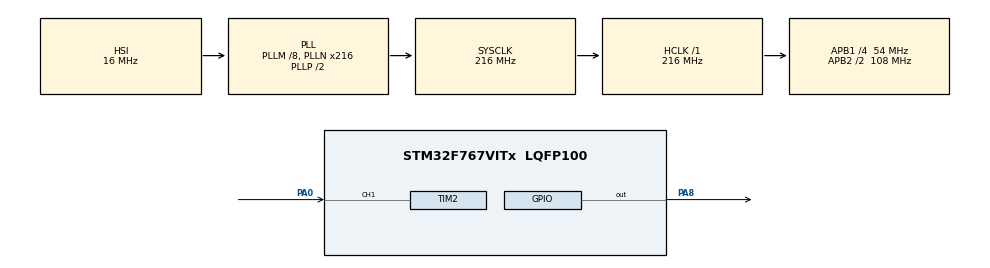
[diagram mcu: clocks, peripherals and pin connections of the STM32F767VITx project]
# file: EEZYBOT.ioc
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FREERTOS.Tasks01=defaultTask,24,128,StartDefaultTask,Default,NULL,Dynamic,NULL,NULL;Blink,8,128,StartBlink,Default,NULL,Dynamic,NULL,NULL
Mcu.Family=STM32F7
Mcu.Name=STM32F767VITx
Mcu.Package=LQFP100
NVIC.PriorityGroup=NVIC_PRIORITYGROUP_4
NVIC.TIM1_UP_TIM10_IRQn=true\:0\:0\:false\:false\:true\:false\:false\:true
NVIC.TIM2_IRQn=true\:5\:0\:false\:false\:true\:true\:true\:true
NVIC.TimeBase=TIM1_UP_TIM10_IRQn
NVIC.TimeBaseIP=TIM1
PA0/WKUP.GPIO_PuPd=GPIO_PULLDOWN
PA0/WKUP.Signal=S_TIM2_CH1_ETR
PA13.Mode=Serial_Wire
PA13.Signal=SYS_JTMS-SWDIO
PA14.Mode=Serial_Wire
PA14.Signal=SYS_JTCK-SWCLK
PA8.Signal=GPIO_Output
ProjectManager.HeapSize=0x200
ProjectManager.StackSize=0x400
ProjectManager.TargetToolchain=STM32CubeIDE
RCC.AHBFreq_Value=216000000
RCC.APB1CLKDivider=RCC_HCLK_DIV4
RCC.APB1Freq_Value=54000000
RCC.APB1TimFreq_Value=108000000
RCC.APB2CLKDivider=RCC_HCLK_DIV2
RCC.APB2Freq_Value=108000000
RCC.APB2TimFreq_Value=216000000
RCC.CortexFreq_Value=216000000
RCC.HCLKFreq_Value=216000000
RCC.HSE_VALUE=25000000
RCC.HSI_VALUE=16000000
RCC.LSE_VALUE=32768
RCC.PLLM=8
RCC.PLLN=216
RCC.SYSCLKFreq_VALUE=216000000
RCC.SYSCLKSource=RCC_SYSCLKSOURCE_PLLCLK
RCC.USBFreq_Value=216000000
RCC.VCOOutputFreq_Value=432000000
SH.S_TIM2_CH1_ETR.0=TIM2_CH1,Input_Capture1_from_TI1
TIM2.Channel-Input_Capture1_from_TI1=TIM_CHANNEL_1
TIM2.ICPolarity_CH1=TIM_INPUTCHANNELPOLARITY_RISING
TIM2.Period=216000
TIM2.Prescaler=0
VP_FREERTOS_VS_CMSIS_V2.Mode=CMSIS_V2
VP_SYS_VS_tim1.Mode=TIM1
board=custom

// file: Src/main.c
/* USER CODE BEGIN Header */
/**
  ******************************************************************************
  * @file           : main.c
  * @brief          : Main program body
  ******************************************************************************
  * @attention
  *
  * <h2><center>&copy; Copyright (c) 2020 STMicroelectronics.
  * All rights reserved.</center></h2>
  *
  * This software component is licensed by ST under BSD 3-Clause license,
  * the "License"; You may not use this file except in compliance with the
  * License. You may obtain a copy of the License at:
  *                        opensource.org/licenses/BSD-3-Clause
  *
  ******************************************************************************
  */
/* USER CODE END Header */

#include "main.h"
#include "cmsis_os.h"

/* USER CODE BEGIN Includes */
#include "AS5048.h"
/* USER CODE END Includes */

TIM_HandleTypeDef htim2;

/* Definitions for defaultTask */
osThreadId_t defaultTaskHandle;
const osThreadAttr_t defaultTask_attributes = {
  .name = "defaultTask",
  .priority = (osPriority_t) osPriorityNormal,
  .stack_size = 128 * 4
};
/* Definitions for Blink */
osThreadId_t BlinkHandle;
const osThreadAttr_t Blink_attributes = {
  .name = "Blink",
  .priority = (osPriority_t) osPriorityLow,
  .stack_size = 128 * 4
};

void SystemClock_Config(void);
static void MX_GPIO_Init(void);
static void MX_TIM2_Init(void);
void StartDefaultTask(void *argument);
void StartBlink(void *argument);

/* USER CODE BEGIN 0 */

AS5048_PWM_SENSOR position_sensors[3];

void HAL_TIM_IC_CaptureCallback(TIM_HandleTypeDef *htim){

	// Check if interrupt came from one of the sensors, then handle it
	for(int i = 0; i < 3; i++)
		if(htim->Instance == position_sensors[i].instance && htim->Channel == position_sensors[i].channel)
			AS5048_pwm_timer_interrupt(&position_sensors[i]);
}

/* USER CODE END 0 */

int main(void)
{

  /* MCU Configuration--------------------------------------------------------*/

  /* Reset of all peripherals, Initializes the Flash interface and the Systick. */
  HAL_Init();

  /* Configure the system clock */
  SystemClock_Config();

  /* Initialize all configured peripherals */
  MX_GPIO_Init();
  MX_TIM2_Init();
  /* USER CODE BEGIN 2 */

  HAL_TIM_IC_Start_IT(&htim2, TIM_CHANNEL_1);
  // Initialise sensor with timer
  AS5048_initialise_struct(&position_sensors[0], &htim2, TIM2, HAL_TIM_ACTIVE_CHANNEL_1, TIM_CHANNEL_1, 108000000);

  /* USER CODE END 2 */

  /* Init scheduler */
  osKernelInitialize();

  /* Create the thread(s) */
  /* creation of defaultTask */
  defaultTaskHandle = osThreadNew(StartDefaultTask, NULL, &defaultTask_attributes);

  /* creation of Blink */
  BlinkHandle = osThreadNew(StartBlink, NULL, &Blink_attributes);

  /* Start scheduler */
  osKernelStart();

  /* We should never get here as control is now taken by the scheduler */
  /* Infinite loop */
  while (1)
  {

  }
}

void SystemClock_Config(void)
{
  RCC_OscInitTypeDef RCC_OscInitStruct = {0};
  RCC_ClkInitTypeDef RCC_ClkInitStruct = {0};

  /** Configure the main internal regulator output voltage
  */
  __HAL_RCC_PWR_CLK_ENABLE();
  __HAL_PWR_VOLTAGESCALING_CONFIG(PWR_REGULATOR_VOLTAGE_SCALE1);
  /** Initializes the CPU, AHB and APB busses clocks
  */
  RCC_OscInitStruct.OscillatorType = RCC_OSCILLATORTYPE_HSI;
  RCC_OscInitStruct.HSIState = RCC_HSI_ON;
  RCC_OscInitStruct.HSICalibrationValue = RCC_HSICALIBRATION_DEFAULT;
  RCC_OscInitStruct.PLL.PLLState = RCC_PLL_ON;
  RCC_OscInitStruct.PLL.PLLSource = RCC_PLLSOURCE_HSI;
  RCC_OscInitStruct.PLL.PLLM = 8;
  RCC_OscInitStruct.PLL.PLLN = 216;
  RCC_OscInitStruct.PLL.PLLP = RCC_PLLP_DIV2;
  RCC_OscInitStruct.PLL.PLLQ = 2;
  if (HAL_RCC_OscConfig(&RCC_OscInitStruct) != HAL_OK)
  {
    Error_Handler();
  }
  /** Activate the Over-Drive mode
  */
  if (HAL_PWREx_EnableOverDrive() != HAL_OK)
  {
    Error_Handler();
  }
  /** Initializes the CPU, AHB and APB busses clocks
  */
  RCC_ClkInitStruct.ClockType = RCC_CLOCKTYPE_HCLK|RCC_CLOCKTYPE_SYSCLK
                              |RCC_CLOCKTYPE_PCLK1|RCC_CLOCKTYPE_PCLK2;
  RCC_ClkInitStruct.SYSCLKSource = RCC_SYSCLKSOURCE_PLLCLK;
  RCC_ClkInitStruct.AHBCLKDivider = RCC_SYSCLK_DIV1;
  RCC_ClkInitStruct.APB1CLKDivider = RCC_HCLK_DIV4;
  RCC_ClkInitStruct.APB2CLKDivider = RCC_HCLK_DIV2;

  if (HAL_RCC_ClockConfig(&RCC_ClkInitStruct, FLASH_LATENCY_7) != HAL_OK)
  {
    Error_Handler();
  }
}

static void MX_TIM2_Init(void)
{

  TIM_MasterConfigTypeDef sMasterConfig = {0};
  TIM_IC_InitTypeDef sConfigIC = {0};

  htim2.Instance = TIM2;
  htim2.Init.Prescaler = 0;
  htim2.Init.CounterMode = TIM_COUNTERMODE_UP;
  htim2.Init.Period = 216000;
  htim2.Init.ClockDivision = TIM_CLOCKDIVISION_DIV1;
  htim2.Init.AutoReloadPreload = TIM_AUTORELOAD_PRELOAD_DISABLE;
  if (HAL_TIM_IC_Init(&htim2) != HAL_OK)
  {
    Error_Handler();
  }
  sMasterConfig.MasterOutputTrigger = TIM_TRGO_RESET;
  sMasterConfig.MasterSlaveMode = TIM_MASTERSLAVEMODE_DISABLE;
  if (HAL_TIMEx_MasterConfigSynchronization(&htim2, &sMasterConfig) != HAL_OK)
  {
    Error_Handler();
  }
  sConfigIC.ICPolarity = TIM_INPUTCHANNELPOLARITY_RISING;
  sConfigIC.ICSelection = TIM_ICSELECTION_DIRECTTI;
  sConfigIC.ICPrescaler = TIM_ICPSC_DIV1;
  sConfigIC.ICFilter = 0;
  if (HAL_TIM_IC_ConfigChannel(&htim2, &sConfigIC, TIM_CHANNEL_1) != HAL_OK)
  {
    Error_Handler();
  }

}

static void MX_GPIO_Init(void)
{
  GPIO_InitTypeDef GPIO_InitStruct = {0};

  /* GPIO Ports Clock Enable */
  __HAL_RCC_GPIOA_CLK_ENABLE();

  /*Configure GPIO pin Output Level */
  HAL_GPIO_WritePin(GPIOA, GPIO_PIN_8, GPIO_PIN_RESET);

  /*Configure GPIO pin : PA8 */
  GPIO_InitStruct.Pin = GPIO_PIN_8;
  GPIO_InitStruct.Mode = GPIO_MODE_OUTPUT_PP;
  GPIO_InitStruct.Pull = GPIO_NOPULL;
  GPIO_InitStruct.Speed = GPIO_SPEED_FREQ_LOW;
  HAL_GPIO_Init(GPIOA, &GPIO_InitStruct);

}

void StartDefaultTask(void *argument)
{
  /* USER CODE BEGIN 5 */
  /* Infinite loop */
  for(;;)
  {
    osDelay(1000);
  }
  /* USER CODE END 5 */
}

void StartBlink(void *argument)
{
  /* USER CODE BEGIN StartBlink */
  /* Infinite loop */
  for(;;)
  {
    osDelay(100);
    HAL_GPIO_TogglePin(GPIOA, GPIO_PIN_8); //Toggle LED
  }
  /* USER CODE END StartBlink */
}

 /**
  * @brief  Period elapsed callback in non blocking mode
  * @note   This function is called  when TIM1 interrupt took place, inside
  * HAL_TIM_IRQHandler(). It makes a direct call to HAL_IncTick() to increment
  * a global variable "uwTick" used as application time base.
  * @param  htim : TIM handle
  * @retval None
  */
void HAL_TIM_PeriodElapsedCallback(TIM_HandleTypeDef *htim)
{
  if (htim->Instance == TIM1) {
    HAL_IncTick();
  }
}

void Error_Handler(void)
{
}

/************************ (C) COPYRIGHT STMicroelectronics *****END OF FILE****/
